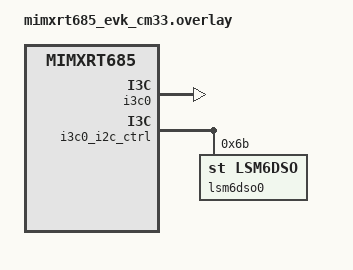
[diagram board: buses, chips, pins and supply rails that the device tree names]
&i3c0 {
	status = "okay";

	/*
	 * There might be other connected I2C devices
	 * (for example, if using Arduino shield) which
	 * cannot tolerate high clock speed. So slow
	 * down the clock.
	 */
	i2c-scl-hz = <400000>;
	i3c-scl-hz = <400000>;
	i3c-od-scl-hz = <400000>;

	clk-divider = <12>;
	clk-divider-slow = <1>;
	clk-divider-tc = <1>;
};

&i3c0_i2c_ctrl {
	status = "okay";

	lsm6dso0: lsm6dso@6b {
		compatible = "st,lsm6dso";
		reg = <0x6b>;

		status = "okay";

//		assigned-address = <0x42>;
	};
};
